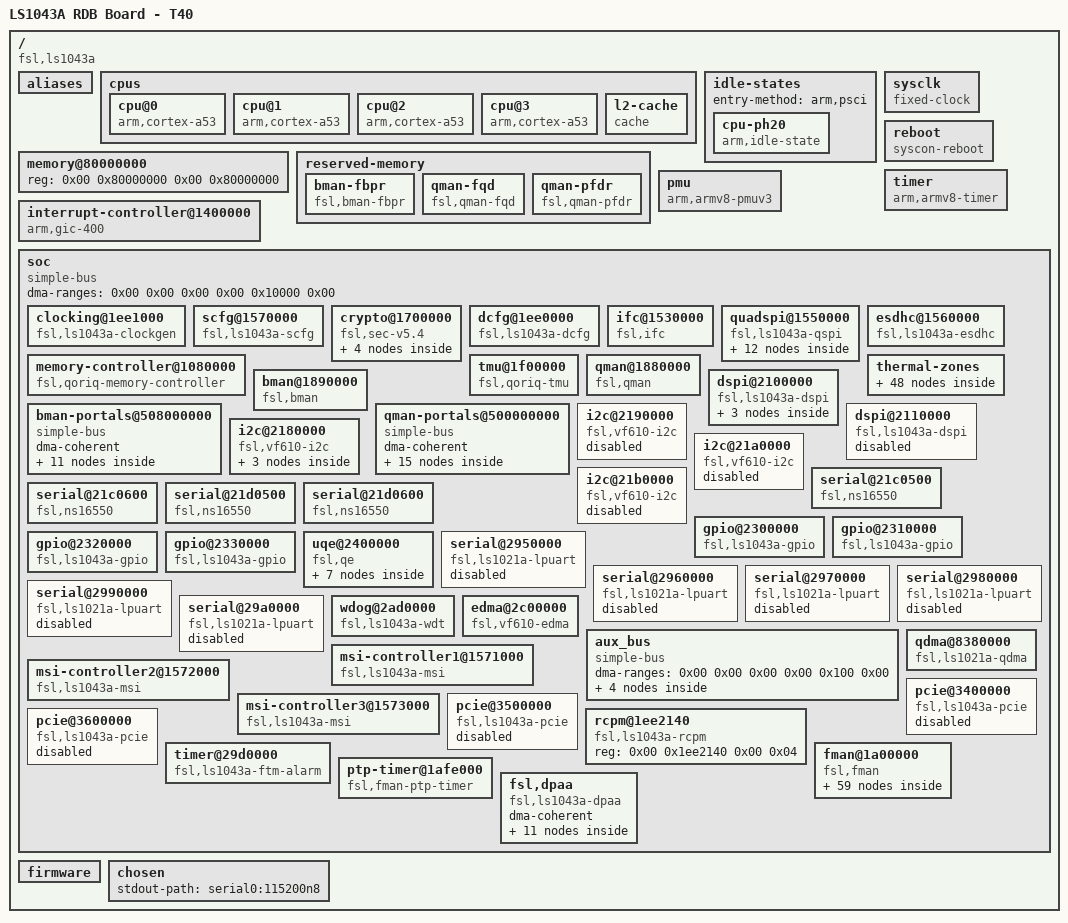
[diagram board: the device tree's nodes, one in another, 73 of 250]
/dts-v1/;

/ {
	compatible = "fsl,ls1043a";
	interrupt-parent = <0x01>;
	#address-cells = <0x02>;
	#size-cells = <0x02>;
	model = "LS1043A RDB Board - T40";

	aliases {
		crypto = "/soc/crypto@1700000";
		fman0 = "/soc/fman@1a00000";
		ethernet0 = "/soc/fman@1a00000/ethernet@e0000";
		ethernet1 = "/soc/fman@1a00000/ethernet@e2000";
		ethernet2 = "/soc/fman@1a00000/ethernet@e4000";
		ethernet3 = "/soc/fman@1a00000/ethernet@e6000";
		ethernet4 = "/soc/fman@1a00000/ethernet@e8000";
		ethernet5 = "/soc/fman@1a00000/ethernet@ea000";
		ethernet6 = "/soc/fman@1a00000/ethernet@f0000";
		rtc1 = "/soc/timer@29d0000";
		serial0 = "/soc/serial@21c0500";
		serial1 = "/soc/serial@21c0600";
		serial2 = "/soc/serial@21d0500";
		serial3 = "/soc/serial@21d0600";
	};

	cpus {
		#address-cells = <0x01>;
		#size-cells = <0x00>;

		cpu@0 {
			device_type = "cpu";
			compatible = "arm,cortex-a53";
			reg = <0x00>;
			clocks = <0x02 0x01 0x00>;
			next-level-cache = <0x03>;
			#cooling-cells = <0x02>;
			cpu-idle-states = <0x04>;
			linux,phandle = <0x06>;
			phandle = <0x06>;
		};

		cpu@1 {
			device_type = "cpu";
			compatible = "arm,cortex-a53";
			reg = <0x01>;
			clocks = <0x02 0x01 0x00>;
			next-level-cache = <0x03>;
			cpu-idle-states = <0x04>;
			linux,phandle = <0x07>;
			phandle = <0x07>;
		};

		cpu@2 {
			device_type = "cpu";
			compatible = "arm,cortex-a53";
			reg = <0x02>;
			clocks = <0x02 0x01 0x00>;
			next-level-cache = <0x03>;
			cpu-idle-states = <0x04>;
			linux,phandle = <0x08>;
			phandle = <0x08>;
		};

		cpu@3 {
			device_type = "cpu";
			compatible = "arm,cortex-a53";
			reg = <0x03>;
			clocks = <0x02 0x01 0x00>;
			next-level-cache = <0x03>;
			cpu-idle-states = <0x04>;
			linux,phandle = <0x09>;
			phandle = <0x09>;
		};

		l2-cache {
			compatible = "cache";
			linux,phandle = <0x03>;
			phandle = <0x03>;
		};
	};

	idle-states {
		entry-method = "arm,psci";

		cpu-ph20 {
			compatible = "arm,idle-state";
			idle-state-name = "PH20";
			arm,psci-suspend-param = <0x00>;
			entry-latency-us = <0x3e8>;
			exit-latency-us = <0x3e8>;
			min-residency-us = <0xbb8>;
			linux,phandle = <0x04>;
			phandle = <0x04>;
		};
	};

	memory@80000000 {
		device_type = "memory";
		reg = <0x00 0x80000000 0x00 0x80000000>;
	};

	reserved-memory {
		#address-cells = <0x02>;
		#size-cells = <0x02>;
		ranges;

		bman-fbpr {
			compatible = "fsl,bman-fbpr";
			size = <0x00 0x1000000>;
			alignment = <0x00 0x1000000>;
			no-map;
			alloc-ranges = <0x00 0x00 0x10000 0x00>;
			linux,phandle = <0x16>;
			phandle = <0x16>;
		};

		qman-fqd {
			compatible = "fsl,qman-fqd";
			size = <0x00 0x400000>;
			alignment = <0x00 0x400000>;
			no-map;
			alloc-ranges = <0x00 0x00 0x10000 0x00>;
			linux,phandle = <0x14>;
			phandle = <0x14>;
		};

		qman-pfdr {
			compatible = "fsl,qman-pfdr";
			size = <0x00 0x2000000>;
			alignment = <0x00 0x2000000>;
			no-map;
			alloc-ranges = <0x00 0x00 0x10000 0x00>;
			linux,phandle = <0x15>;
			phandle = <0x15>;
		};
	};

	sysclk {
		compatible = "fixed-clock";
		#clock-cells = <0x00>;
		clock-frequency = <0x5f5e100>;
		clock-output-names = "sysclk";
		linux,phandle = <0x0a>;
		phandle = <0x0a>;
	};

	reboot {
		compatible = "syscon-reboot";
		regmap = <0x05>;
		offset = <0xb0>;
		mask = <0x02>;
	};

	timer {
		compatible = "arm,armv8-timer";
		interrupts = <0x01 0x0d 0xf08 0x01 0x0e 0xf08 0x01 0x0b 0xf08 0x01 0x0a 0xf08>;
		fsl,erratum-a008585;
	};

	pmu {
		compatible = "arm,armv8-pmuv3";
		interrupts = <0x00 0x6a 0x04 0x00 0x6b 0x04 0x00 0x5f 0x04 0x00 0x61 0x04>;
		interrupt-affinity = <0x06 0x07 0x08 0x09>;
	};

	interrupt-controller@1400000 {
		compatible = "arm,gic-400";
		#interrupt-cells = <0x03>;
		interrupt-controller;
		reg = <0x00 0x1401000 0x00 0x1000 0x00 0x1402000 0x00 0x2000 0x00 0x1404000 0x00 0x2000 0x00 0x1406000 0x00 0x2000>;
		interrupts = <0x01 0x09 0xf08>;
		linux,phandle = <0x01>;
		phandle = <0x01>;
	};

	soc {
		compatible = "simple-bus";
		#address-cells = <0x02>;
		#size-cells = <0x02>;
		ranges;
		dma-ranges = <0x00 0x00 0x00 0x00 0x10000 0x00>;

		clocking@1ee1000 {
			compatible = "fsl,ls1043a-clockgen";
			reg = <0x00 0x1ee1000 0x00 0x1000>;
			#clock-cells = <0x02>;
			clocks = <0x0a>;
			dma-coherent;
			linux,phandle = <0x02>;
			phandle = <0x02>;
		};

		scfg@1570000 {
			compatible = "fsl,ls1043a-scfg", "syscon";
			reg = <0x00 0x1570000 0x00 0x10000>;
			big-endian;
			dma-coherent;
		};

		crypto@1700000 {
			compatible = "fsl,sec-v5.4", "fsl,sec-v5.0", "fsl,sec-v4.0";
			fsl,sec-era = <0x03>;
			#address-cells = <0x01>;
			#size-cells = <0x01>;
			ranges = <0x00 0x00 0x1700000 0x100000>;
			reg = <0x00 0x1700000 0x00 0x100000>;
			interrupts = <0x00 0x4b 0x04>;
			dma-coherent;

			jr@10000 {
				compatible = "fsl,sec-v5.4-job-ring", "fsl,sec-v5.0-job-ring", "fsl,sec-v4.0-job-ring";
				reg = <0x10000 0x10000>;
				interrupts = <0x00 0x47 0x04>;
			};

			jr@20000 {
				compatible = "fsl,sec-v5.4-job-ring", "fsl,sec-v5.0-job-ring", "fsl,sec-v4.0-job-ring";
				reg = <0x20000 0x10000>;
				interrupts = <0x00 0x48 0x04>;
			};

			jr@30000 {
				compatible = "fsl,sec-v5.4-job-ring", "fsl,sec-v5.0-job-ring", "fsl,sec-v4.0-job-ring";
				reg = <0x30000 0x10000>;
				interrupts = <0x00 0x49 0x04>;
			};

			jr@40000 {
				compatible = "fsl,sec-v5.4-job-ring", "fsl,sec-v5.0-job-ring", "fsl,sec-v4.0-job-ring";
				reg = <0x40000 0x10000>;
				interrupts = <0x00 0x4a 0x04>;
			};
		};

		dcfg@1ee0000 {
			compatible = "fsl,ls1043a-dcfg", "syscon";
			reg = <0x00 0x1ee0000 0x00 0x1000>;
			big-endian;
			dma-coherent;
			linux,phandle = <0x05>;
			phandle = <0x05>;
		};

		ifc@1530000 {
			compatible = "fsl,ifc", "simple-bus";
			reg = <0x00 0x1530000 0x00 0x10000>;
			big-endian;
			interrupts = <0x00 0x2b 0x04>;
			dma-coherent;
		};

		quadspi@1550000 {
			compatible = "fsl,ls1043a-qspi", "fsl,ls1021a-qspi";
			#address-cells = <0x01>;
			#size-cells = <0x00>;
			reg = <0x00 0x1550000 0x00 0x10000 0x00 0x40000000 0x00 0x4000000>;
			reg-names = "QuadSPI", "QuadSPI-memory";
			interrupts = <0x00 0x63 0x04>;
			clock-names = "qspi_en", "qspi";
			clocks = <0x02 0x04 0x00 0x02 0x04 0x00>;
			big-endian;
			status = "okay";
			dma-coherent;
			bus-num = <0x00>;

			flash@0 {
				compatible = "fsl,mx25u3235f", "jedec,spi-nor";
				#address-cells = <0x01>;
				#size-cells = <0x01>;
				spi-max-frequency = <0x2faf080>;
				reg = <0x00>;
				linux,modalias = "fsl_m25p80";
				modal = "mx25u3235f";
				spi-rx-bus-width = <0x04>;
				spi-tx-bus-width = <0x04>;
				mode = <0x00>;

				partition@00000000 {
					reg = <0x00 0x200000>;
					label = "NOR (RO) RCW + E-Hole + U-boot Image";
				};

				partition@00200000 {
					reg = <0x200000 0x10000>;
					label = "NOR (RW) U-Boot ENV";
				};

				partition@00210000 {
					reg = <0x210000 0x10000>;
					label = "NOR (RO) EMPTY Hole 1";
				};

				partition@00220000 {
					reg = <0x220000 0x20000>;
					label = "NOR (RW) FMAN UCODE";
				};

				partition@00240000 {
					reg = <0x240000 0x40000>;
					label = "NOR (RW) E-HOLE 2 or PPA";
				};

				partition@00280000 {
					reg = <0x280000 0x20000>;
					label = "NOR (RW) WG CFG0";
				};

				partition@002A0000 {
					reg = <0x2a0000 0x20000>;
					label = "NOR (RW) WG CFG1";
				};

				partition@002C0000 {
					reg = <0x2c0000 0x20000>;
					label = "NOR (RW) WG MFG";
				};

				partition@002E0000 {
					reg = <0x2e0000 0x20000>;
					label = "NOR (RW) E-HOLE 3";
				};

				partition@00300000 {
					reg = <0x300000 0x20000>;
					label = "NOR (RW) FMAN UCODE Old";
				};

				partition@00320000 {
					reg = <0x320000 0xe0000>;
					label = "NOR (RW) WG bootOpt Data & reserved";
				};
			};
		};

		esdhc@1560000 {
			compatible = "fsl,ls1043a-esdhc", "fsl,esdhc";
			reg = <0x00 0x1560000 0x00 0x10000>;
			interrupts = <0x00 0x3e 0x04>;
			clock-frequency = <0x00>;
			voltage-ranges = <0x708 0x708 0xce4 0xce4>;
			sdhci,auto-cmd12;
			big-endian;
			bus-width = <0x04>;
			dma-coherent;
		};

		memory-controller@1080000 {
			compatible = "fsl,qoriq-memory-controller";
			reg = <0x00 0x1080000 0x00 0x1000>;
			interrupts = <0x00 0x90 0x04>;
			big-endian;
			dma-coherent;
		};

		tmu@1f00000 {
			compatible = "fsl,qoriq-tmu";
			reg = <0x00 0x1f00000 0x00 0x10000>;
			interrupts = <0x00 0x21 0x04>;
			fsl,tmu-range = <0xb0000 0x9002a 0x6004c 0x30062>;
			fsl,tmu-calibration = <0x00 0x23 0x01 0x2a 0x02 0x31 0x03 0x37 0x04 0x3e 0x05 0x44 0x06 0x4b 0x07 0x51 0x08 0x58 0x09 0x5e 0x0a 0x65 0x0b 0x6b 0x10000 0x23 0x10001 0x2b 0x10002 0x33 0x10003 0x3b 0x10004 0x43 0x10005 0x4b 0x10006 0x54 0x10007 0x5c 0x10008 0x64 0x10009 0x6c 0x20000 0x21 0x20001 0x2c 0x20002 0x36 0x20003 0x40 0x20004 0x4b 0x20005 0x55 0x20006 0x5f 0x30000 0x13 0x30001 0x1d 0x30002 0x28 0x30003 0x32>;
			#thermal-sensor-cells = <0x01>;
			dma-coherent;
			linux,phandle = <0x0b>;
			phandle = <0x0b>;
		};

		thermal-zones {

			thermal-zone0 {
				polling-delay-passive = <0x3e8>;
				polling-delay = <0x1388>;
				thermal-sensors = <0x0b 0x00>;
				status = "okay";

				trips {

					alert0 {
						temperature = <0x14c08>;
						hysteresis = <0x7d0>;
						type = "passive";
						linux,phandle = <0x0c>;
						phandle = <0x0c>;
					};

					crit0 {
						temperature = <0x15f90>;
						hysteresis = <0x7d0>;
						type = "critical";
					};
				};

				cooling-maps {

					map0 {
						trip = <0x0c>;
						cooling-device = <0x06 0xffffffff 0xffffffff>;
					};
				};
			};

			thermal-zone1 {
				polling-delay-passive = <0x3e8>;
				polling-delay = <0x1388>;
				thermal-sensors = <0x0b 0x01>;
				status = "okay";

				trips {

					alert1 {
						temperature = <0x14c08>;
						hysteresis = <0x7d0>;
						type = "passive";
						linux,phandle = <0x0d>;
						phandle = <0x0d>;
					};

					crit1 {
						temperature = <0x17318>;
						hysteresis = <0x7d0>;
						type = "critical";
					};
				};

				cooling-maps {

					map0 {
						trip = <0x0d>;
						cooling-device = <0x06 0xffffffff 0xffffffff>;
					};
				};
			};

			thermal-zone2 {
				polling-delay-passive = <0x3e8>;
				polling-delay = <0x1388>;
				thermal-sensors = <0x0b 0x02>;
				status = "okay";

				trips {

					alert2 {
						temperature = <0x14c08>;
						hysteresis = <0x7d0>;
						type = "passive";
						linux,phandle = <0x0e>;
						phandle = <0x0e>;
					};

					crit2 {
						temperature = <0x17318>;
						hysteresis = <0x7d0>;
						type = "critical";
					};
				};

				cooling-maps {

					map0 {
						trip = <0x0e>;
						cooling-device = <0x06 0xffffffff 0xffffffff>;
					};
				};
			};

			thermal-zone3 {
				polling-delay-passive = <0x3e8>;
				polling-delay = <0x1388>;
				thermal-sensors = <0x0b 0x03>;
				status = "okay";

				trips {

					alert3 {
						temperature = <0x14c08>;
						hysteresis = <0x7d0>;
						type = "passive";
						linux,phandle = <0x0f>;
						phandle = <0x0f>;
					};

					crit3 {
						temperature = <0x17318>;
						hysteresis = <0x7d0>;
						type = "critical";
					};
				};

				cooling-maps {

					map0 {
						trip = <0x0f>;
						cooling-device = <0x06 0xffffffff 0xffffffff>;
					};
				};
			};

			thermal-zone4 {
				polling-delay-passive = <0x3e8>;
				polling-delay = <0x1388>;
				thermal-sensors = <0x0b 0x04>;
				status = "okay";

				trips {

					alert4 {
						temperature = <0x14c08>;
						hysteresis = <0x7d0>;
						type = "passive";
						linux,phandle = <0x10>;
						phandle = <0x10>;
					};

					crit4 {
						temperature = <0x17318>;
						hysteresis = <0x7d0>;
						type = "critical";
					};
				};

				cooling-maps {

					map0 {
						trip = <0x10>;
						cooling-device = <0x06 0xffffffff 0xffffffff>;
					};
				};
			};

			thermal-zone5 {
				polling-delay-passive = <0x3e8>;
				polling-delay = <0x1388>;
				thermal-sensors = <0x0b 0x05>;
				status = "disabled";

				trips {

					alert5 {
						temperature = <0x14c08>;
						hysteresis = <0x7d0>;
						type = "passive";
						linux,phandle = <0x11>;
						phandle = <0x11>;
					};

					crit5 {
						temperature = <0x17318>;
						hysteresis = <0x7d0>;
						type = "critical";
					};
				};

				cooling-maps {

					map0 {
						trip = <0x11>;
						cooling-device = <0x06 0xffffffff 0xffffffff>;
					};
				};
			};

			thermal-zone6 {
				polling-delay-passive = <0x3e8>;
				polling-delay = <0x1388>;
				thermal-sensors = <0x0b 0x06>;
				status = "disabled";

				trips {

					alert6 {
						temperature = <0x14c08>;
						hysteresis = <0x7d0>;
						type = "passive";
						linux,phandle = <0x12>;
						phandle = <0x12>;
					};

					crit6 {
						temperature = <0x17318>;
						hysteresis = <0x7d0>;
						type = "critical";
					};
				};

				cooling-maps {

					map0 {
						trip = <0x12>;
						cooling-device = <0x06 0xffffffff 0xffffffff>;
					};
				};
			};

			thermal-zone7 {
				polling-delay-passive = <0x3e8>;
				polling-delay = <0x1388>;
				thermal-sensors = <0x0b 0x07>;
				status = "disabled";

				trips {

					alert7 {
						temperature = <0x14c08>;
						hysteresis = <0x7d0>;
						type = "passive";
						linux,phandle = <0x13>;
						phandle = <0x13>;
					};

					crit7 {
						temperature = <0x17318>;
						hysteresis = <0x7d0>;
						type = "critical";
					};
				};

				cooling-maps {

					map0 {
						trip = <0x13>;
						cooling-device = <0x06 0xffffffff 0xffffffff>;
					};
				};
			};
		};

		qman@1880000 {
			compatible = "fsl,qman";
			reg = <0x00 0x1880000 0x00 0x10000>;
			interrupts = <0x00 0x2d 0x04>;
			memory-region = <0x14 0x15>;
			dma-coherent;
		};

		bman@1890000 {
			compatible = "fsl,bman";
			reg = <0x00 0x1890000 0x00 0x10000>;
			interrupts = <0x00 0x2d 0x04>;
			memory-region = <0x16>;
			dma-coherent;
		};

		bman-portals@508000000 {
			ranges = <0x00 0x05 0x8000000 0x8000000>;
			#address-cells = <0x01>;
			#size-cells = <0x01>;
			compatible = "simple-bus";
			dma-coherent;

			bman-portal@0 {
				compatible = "fsl,bman-portal";
				reg = <0x00 0x4000 0x4000000 0x4000>;
				interrupts = <0x00 0xad 0x04>;
				cell-index = <0x00>;
			};

			bman-portal@10000 {
				compatible = "fsl,bman-portal";
				reg = <0x10000 0x4000 0x4010000 0x4000>;
				interrupts = <0x00 0xaf 0x04>;
				cell-index = <0x01>;
			};

			bman-portal@20000 {
				compatible = "fsl,bman-portal";
				reg = <0x20000 0x4000 0x4020000 0x4000>;
				interrupts = <0x00 0xb1 0x04>;
				cell-index = <0x02>;
			};

			bman-portal@30000 {
				compatible = "fsl,bman-portal";
				reg = <0x30000 0x4000 0x4030000 0x4000>;
				interrupts = <0x00 0xb3 0x04>;
				cell-index = <0x03>;
			};

			bman-portal@40000 {
				compatible = "fsl,bman-portal";
				reg = <0x40000 0x4000 0x4040000 0x4000>;
				interrupts = <0x00 0xb5 0x04>;
				cell-index = <0x04>;
			};

			bman-portal@50000 {
				compatible = "fsl,bman-portal";
				reg = <0x50000 0x4000 0x4050000 0x4000>;
				interrupts = <0x00 0xb7 0x04>;
				cell-index = <0x05>;
			};

			bman-portal@60000 {
				compatible = "fsl,bman-portal";
				reg = <0x60000 0x4000 0x4060000 0x4000>;
				interrupts = <0x00 0xb9 0x04>;
				cell-index = <0x06>;
			};

			bman-portal@70000 {
				compatible = "fsl,bman-portal";
				reg = <0x70000 0x4000 0x4070000 0x4000>;
				interrupts = <0x00 0xbb 0x04>;
				cell-index = <0x07>;
			};

			bman-portal@80000 {
				compatible = "fsl,bman-portal";
				reg = <0x80000 0x4000 0x4080000 0x4000>;
				interrupts = <0x00 0xbd 0x04>;
				cell-index = <0x08>;
			};

			bman-portal@90000 {
				compatible = "fsl,bman-portal";
				reg = <0x90000 0x4000 0x4090000 0x4000>;
				interrupts = <0x00 0xbf 0x04>;
				cell-index = <0x09>;
			};

			bman-bpids@0 {
				compatible = "fsl,bpid-range";
				fsl,bpid-range = <0x20 0x20>;
			};
		};

		qman-portals@500000000 {
			ranges = <0x00 0x05 0x00 0x8000000>;
			#address-cells = <0x01>;
			#size-cells = <0x01>;
			compatible = "simple-bus";
			dma-coherent;

			qman-portal@0 {
				compatible = "fsl,qman-portal";
				reg = <0x00 0x4000 0x4000000 0x4000>;
				interrupts = <0x00 0xac 0x04>;
				cell-index = <0x00>;
			};

			qman-portal@10000 {
				compatible = "fsl,qman-portal";
				reg = <0x10000 0x4000 0x4010000 0x4000>;
				interrupts = <0x00 0xae 0x04>;
				cell-index = <0x01>;
			};

			qman-portal@20000 {
				compatible = "fsl,qman-portal";
				reg = <0x20000 0x4000 0x4020000 0x4000>;
				interrupts = <0x00 0xb0 0x04>;
				cell-index = <0x02>;
			};

			qman-portal@30000 {
				compatible = "fsl,qman-portal";
				reg = <0x30000 0x4000 0x4030000 0x4000>;
				interrupts = <0x00 0xb2 0x04>;
				cell-index = <0x03>;
			};

			qman-portal@40000 {
				compatible = "fsl,qman-portal";
				reg = <0x40000 0x4000 0x4040000 0x4000>;
				interrupts = <0x00 0xb4 0x04>;
				cell-index = <0x04>;
			};

			qman-portal@50000 {
				compatible = "fsl,qman-portal";
				reg = <0x50000 0x4000 0x4050000 0x4000>;
				interrupts = <0x00 0xb6 0x04>;
				cell-index = <0x05>;
			};

			qman-portal@60000 {
				compatible = "fsl,qman-portal";
				reg = <0x60000 0x4000 0x4060000 0x4000>;
				interrupts = <0x00 0xb8 0x04>;
				cell-index = <0x06>;
			};

			qman-portal@70000 {
				compatible = "fsl,qman-portal";
				reg = <0x70000 0x4000 0x4070000 0x4000>;
				interrupts = <0x00 0xba 0x04>;
				cell-index = <0x07>;
			};

			qman-portal@80000 {
				compatible = "fsl,qman-portal";
				reg = <0x80000 0x4000 0x4080000 0x4000>;
				interrupts = <0x00 0xbc 0x04>;
				cell-index = <0x08>;
			};

			qman-portal@90000 {
				compatible = "fsl,qman-portal";
				reg = <0x90000 0x4000 0x4090000 0x4000>;
				interrupts = <0x00 0xbe 0x04>;
				cell-index = <0x09>;
			};

			qman-fqids@0 {
				compatible = "fsl,fqid-range";
				fsl,fqid-range = <0x100 0x100>;
			};

			qman-fqids@1 {
				compatible = "fsl,fqid-range";
				fsl,fqid-range = <0x8000 0x8000>;
			};

			qman-pools@0 {
				compatible = "fsl,pool-channel-range";
				fsl,pool-channel-range = <0x401 0x0f>;
			};

			qman-cgrids@0 {
				compatible = "fsl,cgrid-range";
				fsl,cgrid-range = <0x00 0x100>;
			};

			qman-ceetm@0 {
				compatible = "fsl,qman-ceetm";
				fsl,ceetm-lfqid-range = <0xf00000 0x1000>;
				fsl,ceetm-sp-range = <0x00 0x10>;
				fsl,ceetm-lni-range = <0x00 0x08>;
				fsl,ceetm-channel-range = <0x00 0x20>;
			};
		};

		dspi@2100000 {
			compatible = "fsl,ls1043a-dspi", "fsl,ls1021a-v1.0-dspi";
			#address-cells = <0x01>;
			#size-cells = <0x00>;
			reg = <0x00 0x2100000 0x00 0x10000>;
			interrupts = <0x00 0x40 0x04>;
			clock-names = "dspi";
			clocks = <0x02 0x04 0x00>;
			spi-num-chipselects = <0x05>;
			big-endian;
			status = "okay";
			bus-num = <0x00>;
			dma-coherent;

			flash@0 {
				#address-cells = <0x01>;
				#size-cells = <0x01>;
				compatible = "n25q128a13", "jedec,spi-nor";
				reg = <0x00>;
				spi-max-frequency = <0xf4240>;
			};

			slic@2 {
				compatible = "maxim,ds26522";
				reg = <0x02>;
				spi-max-frequency = <0x1e8480>;
				fsl,spi-cs-sck-delay = <0x64>;
				fsl,spi-sck-cs-delay = <0x32>;
			};

			slic@3 {
				compatible = "maxim,ds26522";
				reg = <0x03>;
				spi-max-frequency = <0x1e8480>;
				fsl,spi-cs-sck-delay = <0x64>;
				fsl,spi-sck-cs-delay = <0x32>;
			};
		};

		dspi@2110000 {
			compatible = "fsl,ls1043a-dspi", "fsl,ls1021a-v1.0-dspi";
			#address-cells = <0x01>;
			#size-cells = <0x00>;
			reg = <0x00 0x2110000 0x00 0x10000>;
			interrupts = <0x00 0x41 0x04>;
			clock-names = "dspi";
			clocks = <0x02 0x04 0x00>;
			spi-num-chipselects = <0x05>;
			big-endian;
			status = "disabled";
			dma-coherent;
		};

		i2c@2180000 {
			compatible = "fsl,vf610-i2c", "fsl,ls1043a-vf610-i2c";
			#address-cells = <0x01>;
			#size-cells = <0x00>;
			reg = <0x00 0x2180000 0x00 0x10000>;
			interrupts = <0x00 0x38 0x04>;
			clock-names = "i2c";
			clocks = <0x02 0x04 0x00>;
			dmas = <0x17 0x01 0x27 0x17 0x01 0x26>;
			dma-names = "tx", "rx";
			scl-gpios = <0x18 0x0c 0x00>;
			status = "okay";

			tpm@29 {
				compatible = "atmel,at97sc3204t";
				reg = <0x29>;
			};

			s35390a@30 {
				compatible = "sii,s35390a";
				reg = <0x30>;
			};

			eeprom@50 {
				compatible = "atmel,24c02";
				reg = <0x50>;
			};
		};

		i2c@2190000 {
			compatible = "fsl,vf610-i2c";
			#address-cells = <0x01>;
			#size-cells = <0x00>;
			reg = <0x00 0x2190000 0x00 0x10000>;
			interrupts = <0x00 0x39 0x04>;
			clock-names = "i2c";
			clocks = <0x02 0x04 0x00>;
			status = "disabled";
		};

		i2c@21a0000 {
			compatible = "fsl,vf610-i2c";
			#address-cells = <0x01>;
			#size-cells = <0x00>;
			reg = <0x00 0x21a0000 0x00 0x10000>;
			interrupts = <0x00 0x3a 0x04>;
			clock-names = "i2c";
			clocks = <0x02 0x04 0x00>;
			status = "disabled";
		};

		i2c@21b0000 {
			compatible = "fsl,vf610-i2c";
			#address-cells = <0x01>;
			#size-cells = <0x00>;
			reg = <0x00 0x21b0000 0x00 0x10000>;
			interrupts = <0x00 0x3b 0x04>;
			clock-names = "i2c";
			clocks = <0x02 0x04 0x00>;
			status = "disabled";
		};

		serial@21c0500 {
			compatible = "fsl,ns16550", "ns16550a";
			reg = <0x00 0x21c0500 0x00 0x100>;
			interrupts = <0x00 0x36 0x04>;
			clocks = <0x02 0x04 0x00>;
			status = "okay";
			dma-coherent;
		};

		serial@21c0600 {
			compatible = "fsl,ns16550", "ns16550a";
			reg = <0x00 0x21c0600 0x00 0x100>;
			interrupts = <0x00 0x36 0x04>;
			clocks = <0x02 0x04 0x00>;
			status = "okay";
			dma-coherent;
		};

		serial@21d0500 {
			compatible = "fsl,ns16550", "ns16550a";
			reg = <0x00 0x21d0500 0x00 0x100>;
			interrupts = <0x00 0x37 0x04>;
			clocks = <0x02 0x04 0x00>;
			dma-coherent;
		};

		serial@21d0600 {
			compatible = "fsl,ns16550", "ns16550a";
			reg = <0x00 0x21d0600 0x00 0x100>;
			interrupts = <0x00 0x37 0x04>;
			clocks = <0x02 0x04 0x00>;
			dma-coherent;
		};

		gpio@2300000 {
			compatible = "fsl,ls1043a-gpio", "fsl,qoriq-gpio";
			reg = <0x00 0x2300000 0x00 0x10000>;
			interrupts = <0x00 0x42 0x04>;
			gpio-controller;
			#gpio-cells = <0x02>;
			interrupt-controller;
			#interrupt-cells = <0x02>;
			dma-coherent;
		};

		gpio@2310000 {
			compatible = "fsl,ls1043a-gpio", "fsl,qoriq-gpio";
			reg = <0x00 0x2310000 0x00 0x10000>;
			interrupts = <0x00 0x43 0x04>;
			gpio-controller;
			#gpio-cells = <0x02>;
			interrupt-controller;
			#interrupt-cells = <0x02>;
			dma-coherent;
		};

		gpio@2320000 {
			compatible = "fsl,ls1043a-gpio", "fsl,qoriq-gpio";
			reg = <0x00 0x2320000 0x00 0x10000>;
			interrupts = <0x00 0x44 0x04>;
			gpio-controller;
			#gpio-cells = <0x02>;
			interrupt-controller;
			#interrupt-cells = <0x02>;
			dma-coherent;
		};

		gpio@2330000 {
			compatible = "fsl,ls1043a-gpio", "fsl,qoriq-gpio";
			reg = <0x00 0x2330000 0x00 0x10000>;
			interrupts = <0x00 0x86 0x04>;
			gpio-controller;
			#gpio-cells = <0x02>;
			interrupt-controller;
			#interrupt-cells = <0x02>;
			dma-coherent;
			linux,phandle = <0x18>;
			phandle = <0x18>;
		};

		uqe@2400000 {
			#address-cells = <0x01>;
			#size-cells = <0x01>;
			device_type = "qe";
			compatible = "fsl,qe", "simple-bus";
			ranges = <0x00 0x00 0x2400000 0x40000>;
			reg = <0x00 0x2400000 0x00 0x480>;
			brg-frequency = <0x5f5e100>;
			bus-frequency = <0xbebc200>;
			fsl,qe-num-riscs = <0x01>;
			fsl,qe-num-snums = <0x1c>;

			qeic@80 {
				compatible = "fsl,qe-ic";
				reg = <0x80 0x80>;
				#address-cells = <0x00>;
				interrupt-controller;
				#interrupt-cells = <0x01>;
				interrupts = <0x00 0x4d 0x04 0x00 0x4d 0x04>;
				linux,phandle = <0x19>;
				phandle = <0x19>;
			};

			si@700 {
				#address-cells = <0x01>;
				#size-cells = <0x00>;
				compatible = "fsl,ls1043-qe-si", "fsl,t1040-qe-si";
				reg = <0x700 0x80>;
			};

			siram@1000 {
				#address-cells = <0x01>;
				#size-cells = <0x01>;
				compatible = "fsl,ls1043-qe-siram", "fsl,t1040-qe-siram";
				reg = <0x1000 0x800>;
			};

			ucc@2000 {
				cell-index = <0x01>;
				reg = <0x2000 0x200>;
				interrupts = <0x20>;
				interrupt-parent = <0x19>;
				compatible = "fsl,ucc-hdlc";
				rx-clock-name = "clk8";
				tx-clock-name = "clk9";
				fsl,rx-sync-clock = "rsync_pin";
				fsl,tx-sync-clock = "tsync_pin";
				fsl,tx-timeslot-mask = <0xfffffffe>;
				fsl,rx-timeslot-mask = <0xfffffffe>;
				fsl,tdm-framer-type = "e1";
				fsl,tdm-id = <0x00>;
				fsl,siram-entry-id = <0x00>;
				fsl,tdm-interface;
			};

			ucc@2200 {
				cell-index = <0x03>;
				reg = <0x2200 0x200>;
				interrupts = <0x22>;
				interrupt-parent = <0x19>;
			};

			muram@10000 {
				#address-cells = <0x01>;
				#size-cells = <0x01>;
				compatible = "fsl,qe-muram", "fsl,cpm-muram";
				ranges = <0x00 0x10000 0x6000>;

				data-only@0 {
					compatible = "fsl,qe-muram-data", "fsl,cpm-muram-data";
					reg = <0x00 0x6000>;
				};
			};
		};

		serial@2950000 {
			compatible = "fsl,ls1021a-lpuart";
			reg = <0x00 0x2950000 0x00 0x1000>;
			interrupts = <0x00 0x30 0x04>;
			clocks = <0x02 0x00 0x00>;
			clock-names = "ipg";
			status = "disabled";
			dma-coherent;
		};

		serial@2960000 {
			compatible = "fsl,ls1021a-lpuart";
			reg = <0x00 0x2960000 0x00 0x1000>;
			interrupts = <0x00 0x31 0x04>;
			clocks = <0x02 0x04 0x00>;
			clock-names = "ipg";
			status = "disabled";
			dma-coherent;
		};

		serial@2970000 {
			compatible = "fsl,ls1021a-lpuart";
			reg = <0x00 0x2970000 0x00 0x1000>;
			interrupts = <0x00 0x32 0x04>;
			clocks = <0x02 0x04 0x00>;
			clock-names = "ipg";
			status = "disabled";
			dma-coherent;
		};

		serial@2980000 {
			compatible = "fsl,ls1021a-lpuart";
			reg = <0x00 0x2980000 0x00 0x1000>;
			interrupts = <0x00 0x33 0x04>;
			clocks = <0x02 0x04 0x00>;
			clock-names = "ipg";
			status = "disabled";
			dma-coherent;
		};

		serial@2990000 {
			compatible = "fsl,ls1021a-lpuart";
			reg = <0x00 0x2990000 0x00 0x1000>;
			interrupts = <0x00 0x34 0x04>;
			clocks = <0x02 0x04 0x00>;
			clock-names = "ipg";
			status = "disabled";
			dma-coherent;
		};

		serial@29a0000 {
			compatible = "fsl,ls1021a-lpuart";
			reg = <0x00 0x29a0000 0x00 0x1000>;
			interrupts = <0x00 0x35 0x04>;
			clocks = <0x02 0x04 0x00>;
			clock-names = "ipg";
			status = "disabled";
			dma-coherent;
		};

		wdog@2ad0000 {
			compatible = "fsl,ls1043a-wdt", "fsl,imx21-wdt";
			reg = <0x00 0x2ad0000 0x00 0x10000>;
			interrupts = <0x00 0x53 0x04>;
			clocks = <0x02 0x04 0x00>;
			clock-names = "wdog";
			big-endian;
			dma-coherent;
		};

		edma@2c00000 {
			#dma-cells = <0x02>;
			compatible = "fsl,vf610-edma";
			reg = <0x00 0x2c00000 0x00 0x10000 0x00 0x2c10000 0x00 0x10000 0x00 0x2c20000 0x00 0x10000>;
			interrupts = <0x00 0x67 0x04 0x00 0x67 0x04>;
			interrupt-names = "edma-tx", "edma-err";
			dma-channels = <0x20>;
			big-endian;
			clock-names = "dmamux0", "dmamux1";
			clocks = <0x02 0x04 0x00 0x02 0x04 0x00>;
			linux,phandle = <0x17>;
			phandle = <0x17>;
		};

		aux_bus {
			#address-cells = <0x02>;
			#size-cells = <0x02>;
			compatible = "simple-bus";
			ranges;
			dma-ranges = <0x00 0x00 0x00 0x00 0x100 0x00>;

			usb3@2f00000 {
				compatible = "snps,dwc3";
				reg = <0x00 0x2f00000 0x00 0x10000>;
				interrupts = <0x00 0x3c 0x04>;
				dr_mode = "host";
				snps,quirk-frame-length-adjustment = <0x20>;
				snps,dis_rxdet_inp3_quirk;
				usb3-lpm-capable;
				snps,dis-u1u2-when-u3-quirk;
				snps,incr-burst-type-adjustment = <0x01 0x04 0x08 0x10>;
				snps,host-vbus-glitches;
			};

			usb3@3000000 {
				compatible = "snps,dwc3";
				reg = <0x00 0x3000000 0x00 0x10000>;
				interrupts = <0x00 0x3d 0x04>;
				dr_mode = "host";
				snps,quirk-frame-length-adjustment = <0x20>;
				snps,dis_rxdet_inp3_quirk;
				usb3-lpm-capable;
				snps,dis-u1u2-when-u3-quirk;
				snps,incr-burst-type-adjustment = <0x01 0x04 0x08 0x10>;
				snps,host-vbus-glitches;
			};

			usb3@3100000 {
				compatible = "snps,dwc3";
				reg = <0x00 0x3100000 0x00 0x10000>;
				interrupts = <0x00 0x3f 0x04>;
				dr_mode = "host";
				snps,quirk-frame-length-adjustment = <0x20>;
				snps,dis_rxdet_inp3_quirk;
				usb3-lpm-capable;
				snps,dis-u1u2-when-u3-quirk;
				snps,incr-burst-type-adjustment = <0x01 0x04 0x08 0x10>;
				snps,host-vbus-glitches;
			};

			sata@3200000 {
				compatible = "fsl,ls1043a-ahci";
				reg = <0x00 0x3200000 0x00 0x10000 0x00 0x20140520 0x00 0x04>;
				reg-names = "ahci", "sata-ecc";
				interrupts = <0x00 0x45 0x04>;
				clocks = <0x02 0x04 0x00>;
			};
		};

		qdma@8380000 {
			compatible = "fsl,ls1021a-qdma", "fsl,ls1043a-qdma";
			reg = <0x00 0x8380000 0x00 0x1000 0x00 0x8390000 0x00 0x10000 0x00 0x83a0000 0x00 0x40000>;
			interrupts = <0x00 0x98 0x04 0x00 0x27 0x04 0x00 0x28 0x04 0x00 0x29 0x04 0x00 0x2a 0x04>;
			interrupt-names = "qdma-error", "qdma-queue0", "qdma-queue1", "qdma-queue2", "qdma-queue3";
			channels = <0x08>;
			block-number = <0x01>;
			block-offset = <0x10000>;
			queues = <0x02>;
			status-sizes = <0x40>;
			queue-sizes = <0x40 0x40>;
			big-endian;
			dma-coherent;
		};

		msi-controller1@1571000 {
			compatible = "fsl,ls1043a-msi";
			reg = <0x00 0x1571000 0x00 0x08>;
			msi-controller;
			interrupts = <0x00 0x74 0x04>;
			dma-coherent;
			linux,phandle = <0x1a>;
			phandle = <0x1a>;
		};

		msi-controller2@1572000 {
			compatible = "fsl,ls1043a-msi";
			reg = <0x00 0x1572000 0x00 0x08>;
			msi-controller;
			interrupts = <0x00 0x7e 0x04>;
			dma-coherent;
			linux,phandle = <0x1b>;
			phandle = <0x1b>;
		};

		msi-controller3@1573000 {
			compatible = "fsl,ls1043a-msi";
			reg = <0x00 0x1573000 0x00 0x08>;
			msi-controller;
			interrupts = <0x00 0xa0 0x04>;
			dma-coherent;
			linux,phandle = <0x1c>;
			phandle = <0x1c>;
		};

		pcie@3400000 {
			compatible = "fsl,ls1043a-pcie", "snps,dw-pcie";
			reg = <0x00 0x3400000 0x00 0x100000 0x40 0x00 0x00 0x2000>;
			reg-names = "regs", "config";
			interrupts = <0x00 0x75 0x04 0x00 0x76 0x04>;
			interrupt-names = "pme", "aer";
			#address-cells = <0x03>;
			#size-cells = <0x02>;
			device_type = "pci";
			bus-range = <0x00 0xff>;
			ranges = <0x81000000 0x00 0x00 0x40 0x10000 0x00 0x10000 0x82000000 0x00 0x40000000 0x40 0x40000000 0x00 0x40000000>;
			msi-parent = <0x1a 0x1b 0x1c>;
			#interrupt-cells = <0x01>;
			interrupt-map-mask = <0x00 0x00 0x00 0x07>;
			interrupt-map = <0x00 0x00 0x00 0x01 0x01 0x00 0x6e 0x04 0x00 0x00 0x00 0x02 0x01 0x00 0x6f 0x04 0x00 0x00 0x00 0x03 0x01 0x00 0x70 0x04 0x00 0x00 0x00 0x04 0x01 0x00 0x71 0x04>;
			status = "disabled";
			dma-coherent;
		};

		pcie@3500000 {
			compatible = "fsl,ls1043a-pcie", "snps,dw-pcie";
			reg = <0x00 0x3500000 0x00 0x100000 0x48 0x00 0x00 0x2000>;
			reg-names = "regs", "config";
			interrupts = <0x00 0x7f 0x04 0x00 0x80 0x04>;
			interrupt-names = "pme", "aer";
			#address-cells = <0x03>;
			#size-cells = <0x02>;
			device_type = "pci";
			bus-range = <0x00 0xff>;
			ranges = <0x81000000 0x00 0x00 0x48 0x10000 0x00 0x10000 0x82000000 0x00 0x40000000 0x48 0x40000000 0x00 0x40000000>;
			msi-parent = <0x1a 0x1b 0x1c>;
			#interrupt-cells = <0x01>;
			interrupt-map-mask = <0x00 0x00 0x00 0x07>;
			interrupt-map = <0x00 0x00 0x00 0x01 0x01 0x00 0x78 0x04 0x00 0x00 0x00 0x02 0x01 0x00 0x79 0x04 0x00 0x00 0x00 0x03 0x01 0x00 0x7a 0x04 0x00 0x00 0x00 0x04 0x01 0x00 0x7b 0x04>;
			status = "disabled";
			dma-coherent;
		};

		pcie@3600000 {
			compatible = "fsl,ls1043a-pcie", "snps,dw-pcie";
			reg = <0x00 0x3600000 0x00 0x100000 0x50 0x00 0x00 0x2000>;
			reg-names = "regs", "config";
			interrupts = <0x00 0xa1 0x04 0x00 0xa2 0x04>;
			interrupt-names = "pme", "aer";
			#address-cells = <0x03>;
			#size-cells = <0x02>;
			device_type = "pci";
			bus-range = <0x00 0xff>;
			ranges = <0x81000000 0x00 0x00 0x50 0x10000 0x00 0x10000 0x82000000 0x00 0x40000000 0x50 0x40000000 0x00 0x40000000>;
			msi-parent = <0x1a 0x1b 0x1c>;
			#interrupt-cells = <0x01>;
			interrupt-map-mask = <0x00 0x00 0x00 0x07>;
			interrupt-map = <0x00 0x00 0x00 0x01 0x01 0x00 0x9a 0x04 0x00 0x00 0x00 0x02 0x01 0x00 0x9b 0x04 0x00 0x00 0x00 0x03 0x01 0x00 0x9c 0x04 0x00 0x00 0x00 0x04 0x01 0x00 0x9d 0x04>;
			status = "disabled";
			dma-coherent;
		};

		rcpm@1ee2140 {
			compatible = "fsl,ls1043a-rcpm", "fsl,qoriq-rcpm-2.1+";
			reg = <0x00 0x1ee2140 0x00 0x04>;
			#fsl,rcpm-wakeup-cells = <0x01>;
			linux,phandle = <0x1d>;
			phandle = <0x1d>;
		};

		timer@29d0000 {
			compatible = "fsl,ls1043a-ftm-alarm";
			reg = <0x00 0x29d0000 0x00 0x10000>;
			fsl,rcpm-wakeup = <0x1d 0x20000>;
			interrupts = <0x00 0x56 0x04>;
			big-endian;
			dma-coherent;
		};

		fman@1a00000 {
			#address-cells = <0x01>;
			#size-cells = <0x01>;
			cell-index = <0x00>;
			compatible = "fsl,fman", "simple-bus";
			ranges = <0x00 0x00 0x1a00000 0xfe000>;
			reg = <0x00 0x1a00000 0x00 0xfe000>;
			interrupts = <0x00 0x2c 0x04 0x00 0x2d 0x04>;
			clocks = <0x02 0x03 0x00>;
			clock-names = "fmanclk";
			fsl,qman-channel-range = <0x800 0x10>;
			ptimer-handle = <0x1e>;
			fsl,erratum-a050385;
			dma-coherent;

			cc {
				compatible = "fsl,fman-cc";
			};

			muram@0 {
				compatible = "fsl,fman-muram";
				reg = <0x00 0x60000>;
			};

			bmi@80000 {
				compatible = "fsl,fman-bmi";
				reg = <0x80000 0x400>;
			};

			qmi@80400 {
				compatible = "fsl,fman-qmi";
				reg = <0x80400 0x400>;
			};

			port@82000 {
				cell-index = <0x00>;
				compatible = "fsl,fman-port-oh";
				reg = <0x82000 0x1000>;
				fsl,qman-channel-id = <0x809>;
			};

			port@83000 {
				cell-index = <0x01>;
				compatible = "fsl,fman-port-oh";
				reg = <0x83000 0x1000>;
				fsl,qman-channel-id = <0x80a>;
			};

			port@84000 {
				cell-index = <0x02>;
				compatible = "fsl,fman-port-oh";
				reg = <0x84000 0x1000>;
				fsl,qman-channel-id = <0x80b>;
			};

			port@85000 {
				cell-index = <0x03>;
				compatible = "fsl,fman-port-oh";
				reg = <0x85000 0x1000>;
				fsl,qman-channel-id = <0x80c>;
			};

			port@86000 {
				cell-index = <0x04>;
				compatible = "fsl,fman-port-oh";
				reg = <0x86000 0x1000>;
				fsl,qman-channel-id = <0x80d>;
			};

			port@87000 {
				cell-index = <0x05>;
				compatible = "fsl,fman-port-oh";
				reg = <0x87000 0x1000>;
				fsl,qman-channel-id = <0x80e>;
			};

			policer@c0000 {
				compatible = "fsl,fman-policer";
				reg = <0xc0000 0x1000>;
			};

			keygen@c1000 {
				compatible = "fsl,fman-keygen";
				reg = <0xc1000 0x1000>;
			};

			dma@c2000 {
				compatible = "fsl,fman-dma";
				reg = <0xc2000 0x1000>;
			};

			fpm@c3000 {
				compatible = "fsl,fman-fpm";
				reg = <0xc3000 0x1000>;
			};

			parser@c7000 {
				compatible = "fsl,fman-parser";
				reg = <0xc7000 0x1000>;
			};

			vsps@dc000 {
				compatible = "fsl,fman-vsps";
				reg = <0xdc000 0x1000>;
			};

			mdio@fc000 {
				#address-cells = <0x01>;
				#size-cells = <0x00>;
				compatible = "fsl,fman-memac-mdio", "fsl,fman-xmdio";
				reg = <0xfc000 0x1000>;

				ethernet-phy@1 {
					reg = <0x04>;
					linux,phandle = <0x22>;
					phandle = <0x22>;
				};

				ethernet-phy@2 {
					reg = <0x05>;
					linux,phandle = <0x26>;
					phandle = <0x26>;
				};

				ethernet-phy@3 {
					reg = <0x06>;
					linux,phandle = <0x31>;
					phandle = <0x31>;
				};

				ethernet-phy@4 {
					reg = <0x07>;
					linux,phandle = <0x35>;
					phandle = <0x35>;
				};
			};

			mdio@fd000 {
				#address-cells = <0x01>;
				#size-cells = <0x00>;
				compatible = "fsl,fman-memac-mdio", "fsl,fman-xmdio";
				reg = <0xfd000 0x1000>;

				ethernet-phy@1 {
					reg = <0x01>;
					linux,phandle = <0x2a>;
					phandle = <0x2a>;
				};
			};

			port@88000 {
				cell-index = <0x08>;
				compatible = "fsl,fman-v3-port-rx", "fsl,fman-port-1g-rx";
				reg = <0x88000 0x1000>;
				linux,phandle = <0x1f>;
				phandle = <0x1f>;
			};

			port@a8000 {
				cell-index = <0x28>;
				compatible = "fsl,fman-v3-port-tx", "fsl,fman-port-1g-tx";
				reg = <0xa8000 0x1000>;
				fsl,qman-channel-id = <0x802>;
				linux,phandle = <0x20>;
				phandle = <0x20>;
			};

			ethernet@e0000 {
				cell-index = <0x00>;
				compatible = "fsl,fman-memac";
				reg = <0xe0000 0x1000>;
				fsl,fman-ports = <0x1f 0x20>;
				ptp-timer = <0x1e>;
				pcsphy-handle = <0x21>;
				phy-handle = <0x22>;
				linux,phandle = <0x39>;
				phandle = <0x39>;
			};

			mdio@e1000 {
				#address-cells = <0x01>;
				#size-cells = <0x00>;
				compatible = "fsl,fman-memac-mdio", "fsl,fman-xmdio";
				reg = <0xe1000 0x1000>;

				ethernet-phy@0 {
					reg = <0x00>;
					linux,phandle = <0x21>;
					phandle = <0x21>;
				};
			};

			port@89000 {
				cell-index = <0x09>;
				compatible = "fsl,fman-v3-port-rx", "fsl,fman-port-1g-rx";
				reg = <0x89000 0x1000>;
				linux,phandle = <0x23>;
				phandle = <0x23>;
			};

			port@a9000 {
				cell-index = <0x29>;
				compatible = "fsl,fman-v3-port-tx", "fsl,fman-port-1g-tx";
				reg = <0xa9000 0x1000>;
				fsl,qman-channel-id = <0x803>;
				linux,phandle = <0x24>;
				phandle = <0x24>;
			};

			ethernet@e2000 {
				cell-index = <0x01>;
				compatible = "fsl,fman-memac";
				reg = <0xe2000 0x1000>;
				fsl,fman-ports = <0x23 0x24>;
				ptp-timer = <0x1e>;
				pcsphy-handle = <0x25>;
				phy-handle = <0x26>;
				linux,phandle = <0x3a>;
				phandle = <0x3a>;
			};

			mdio@e3000 {
				#address-cells = <0x01>;
				#size-cells = <0x00>;
				compatible = "fsl,fman-memac-mdio", "fsl,fman-xmdio";
				reg = <0xe3000 0x1000>;

				ethernet-phy@0 {
					reg = <0x00>;
					linux,phandle = <0x25>;
					phandle = <0x25>;
				};
			};

			port@8a000 {
				cell-index = <0x0a>;
				compatible = "fsl,fman-v3-port-rx", "fsl,fman-port-1g-rx";
				reg = <0x8a000 0x1000>;
				linux,phandle = <0x27>;
				phandle = <0x27>;
			};

			port@aa000 {
				cell-index = <0x2a>;
				compatible = "fsl,fman-v3-port-tx", "fsl,fman-port-1g-tx";
				reg = <0xaa000 0x1000>;
				fsl,qman-channel-id = <0x804>;
				linux,phandle = <0x28>;
				phandle = <0x28>;
			};

			ethernet@e4000 {
				cell-index = <0x02>;
				compatible = "fsl,fman-memac";
				reg = <0xe4000 0x1000>;
				fsl,fman-ports = <0x27 0x28>;
				ptp-timer = <0x1e>;
				pcsphy-handle = <0x29>;
				phy-handle = <0x2a>;
				linux,phandle = <0x3b>;
				phandle = <0x3b>;
			};

			mdio@e5000 {
				#address-cells = <0x01>;
				#size-cells = <0x00>;
				compatible = "fsl,fman-memac-mdio", "fsl,fman-xmdio";
				reg = <0xe5000 0x1000>;

				ethernet-phy@0 {
					reg = <0x00>;
					linux,phandle = <0x29>;
					phandle = <0x29>;
				};
			};

			port@8b000 {
				cell-index = <0x0b>;
				compatible = "fsl,fman-v3-port-rx", "fsl,fman-port-1g-rx";
				reg = <0x8b000 0x1000>;
				linux,phandle = <0x2b>;
				phandle = <0x2b>;
			};

			port@ab000 {
				cell-index = <0x2b>;
				compatible = "fsl,fman-v3-port-tx", "fsl,fman-port-1g-tx";
				reg = <0xab000 0x1000>;
				fsl,qman-channel-id = <0x805>;
				linux,phandle = <0x2c>;
				phandle = <0x2c>;
			};

			ethernet@e6000 {
				cell-index = <0x03>;
				compatible = "fsl,fman-memac";
				reg = <0xe6000 0x1000>;
				fsl,fman-ports = <0x2b 0x2c>;
				ptp-timer = <0x1e>;
				pcsphy-handle = <0x2d>;
				linux,phandle = <0x3c>;
				phandle = <0x3c>;
			};

			mdio@e7000 {
				#address-cells = <0x01>;
				#size-cells = <0x00>;
				compatible = "fsl,fman-memac-mdio", "fsl,fman-xmdio";
				reg = <0xe7000 0x1000>;

				ethernet-phy@0 {
					reg = <0x00>;
					linux,phandle = <0x2d>;
					phandle = <0x2d>;
				};
			};

			port@8c000 {
				cell-index = <0x0c>;
				compatible = "fsl,fman-v3-port-rx", "fsl,fman-port-1g-rx";
				reg = <0x8c000 0x1000>;
				linux,phandle = <0x2e>;
				phandle = <0x2e>;
			};

			port@ac000 {
				cell-index = <0x2c>;
				compatible = "fsl,fman-v3-port-tx", "fsl,fman-port-1g-tx";
				reg = <0xac000 0x1000>;
				fsl,qman-channel-id = <0x806>;
				linux,phandle = <0x2f>;
				phandle = <0x2f>;
			};

			ethernet@e8000 {
				cell-index = <0x04>;
				compatible = "fsl,fman-memac";
				reg = <0xe8000 0x1000>;
				fsl,fman-ports = <0x2e 0x2f>;
				ptp-timer = <0x1e>;
				pcsphy-handle = <0x30>;
				phy-handle = <0x31>;
				linux,phandle = <0x3d>;
				phandle = <0x3d>;
			};

			mdio@e9000 {
				#address-cells = <0x01>;
				#size-cells = <0x00>;
				compatible = "fsl,fman-memac-mdio", "fsl,fman-xmdio";
				reg = <0xe9000 0x1000>;

				ethernet-phy@0 {
					reg = <0x00>;
					linux,phandle = <0x30>;
					phandle = <0x30>;
				};
			};

			port@8d000 {
				cell-index = <0x0d>;
				compatible = "fsl,fman-v3-port-rx", "fsl,fman-port-1g-rx";
				reg = <0x8d000 0x1000>;
				linux,phandle = <0x32>;
				phandle = <0x32>;
			};

			port@ad000 {
				cell-index = <0x2d>;
				compatible = "fsl,fman-v3-port-tx", "fsl,fman-port-1g-tx";
				reg = <0xad000 0x1000>;
				fsl,qman-channel-id = <0x807>;
				linux,phandle = <0x33>;
				phandle = <0x33>;
			};

			ethernet@ea000 {
				cell-index = <0x05>;
				compatible = "fsl,fman-memac";
				reg = <0xea000 0x1000>;
				fsl,fman-ports = <0x32 0x33>;
				ptp-timer = <0x1e>;
				pcsphy-handle = <0x34>;
				phy-handle = <0x35>;
				linux,phandle = <0x3e>;
				phandle = <0x3e>;
			};

			mdio@eb000 {
				#address-cells = <0x01>;
				#size-cells = <0x00>;
				compatible = "fsl,fman-memac-mdio", "fsl,fman-xmdio";
				reg = <0xeb000 0x1000>;

				ethernet-phy@0 {
					reg = <0x00>;
					linux,phandle = <0x34>;
					phandle = <0x34>;
				};
			};

			port@90000 {
				cell-index = <0x10>;
				compatible = "fsl,fman-v3-port-rx", "fsl,fman-port-10g-rx";
				reg = <0x90000 0x1000>;
				fsl,fman-10g-port;
				linux,phandle = <0x36>;
				phandle = <0x36>;
			};

			port@b0000 {
				cell-index = <0x30>;
				compatible = "fsl,fman-v3-port-tx", "fsl,fman-port-10g-tx";
				reg = <0xb0000 0x1000>;
				fsl,fman-10g-port;
				fsl,qman-channel-id = <0x800>;
				linux,phandle = <0x37>;
				phandle = <0x37>;
			};

			ethernet@f0000 {
				cell-index = <0x08>;
				compatible = "fsl,fman-memac";
				reg = <0xf0000 0x1000>;
				fsl,fman-ports = <0x36 0x37>;
				pcsphy-handle = <0x38>;
				linux,phandle = <0x3f>;
				phandle = <0x3f>;
			};

			mdio@f1000 {
				#address-cells = <0x01>;
				#size-cells = <0x00>;
				compatible = "fsl,fman-memac-mdio", "fsl,fman-xmdio";
				reg = <0xf1000 0x1000>;

				ethernet-phy@0 {
					reg = <0x00>;
					linux,phandle = <0x38>;
					phandle = <0x38>;
				};
			};

			ethernet@f2000 {
			};
		};

		ptp-timer@1afe000 {
			compatible = "fsl,fman-ptp-timer";
			reg = <0x00 0x1afe000 0x00 0x1000>;
			interrupts = <0x00 0x2c 0x04>;
			clocks = <0x02 0x03 0x00>;
			dma-coherent;
			linux,phandle = <0x1e>;
			phandle = <0x1e>;
		};

		fsl,dpaa {
			compatible = "fsl,ls1043a-dpaa", "simple-bus", "fsl,dpaa";
			dma-coherent;

			ethernet@0 {
				compatible = "fsl,dpa-ethernet";
				fsl,fman-mac = <0x39>;
				dma-coherent;
			};

			ethernet@1 {
				compatible = "fsl,dpa-ethernet";
				fsl,fman-mac = <0x3a>;
				dma-coherent;
			};

			ethernet@2 {
				compatible = "fsl,dpa-ethernet";
				fsl,fman-mac = <0x3b>;
				dma-coherent;
			};

			ethernet@3 {
				compatible = "fsl,dpa-ethernet";
				fsl,fman-mac = <0x3c>;
				dma-coherent;
			};

			ethernet@4 {
				compatible = "fsl,dpa-ethernet";
				fsl,fman-mac = <0x3d>;
				dma-coherent;
			};

			ethernet@5 {
				compatible = "fsl,dpa-ethernet";
				fsl,fman-mac = <0x3e>;
				dma-coherent;
			};

			ethernet@8 {
				compatible = "fsl,dpa-ethernet";
				fsl,fman-mac = <0x3f>;
				dma-coherent;
			};

			ethernet@6 {
				compatible = "fsl,im-ethernet";
				fsl,fman-mac = <0x3b>;
				dma-coherent;
				fpmevt-sel = <0x00>;
			};

			ethernet@7 {
				compatible = "fsl,im-ethernet";
				fsl,fman-mac = <0x3c>;
				dma-coherent;
				fpmevt-sel = <0x01>;
			};

			ethernet@10 {
				compatible = "fsl,im-ethernet";
				fsl,fman-mac = <0x3d>;
				dma-coherent;
				fpmevt-sel = <0x02>;
			};

			ethernet@11 {
				compatible = "fsl,im-ethernet";
				fsl,fman-mac = <0x3e>;
				dma-coherent;
				fpmevt-sel = <0x03>;
			};
		};
	};

	firmware {
	};

	chosen {
		stdout-path = "serial0:115200n8";
	};
};
